# STM32F215 register map
File version: 1.2
CPU: CM3 r1p1, little endian, no MPU, no FPU, 4 interrupt priority bits
Registers are 32-bit, read-write, reset 0x0 unless marked. A register's access mark holds for its fields unless they carry their own. Offsets are from the block's base; [hi:lo] are bit positions; {n}, {i} and the like mark numbered series; 'fields as' and 'values as' point back to an identical list.

## RNG — Random number generator
Base 0x50060800
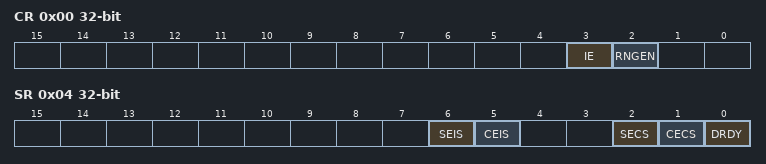
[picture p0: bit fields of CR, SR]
0x00 CR — control register
  [3] IE — Interrupt enable
  [2] RNGEN — Random number generator enable
0x04 SR access per field — status register
  [6] SEIS rw — Seed error interrupt status
  [5] CEIS rw — Clock error interrupt status
  [2] SECS ro — Seed error current status
  [1] CECS ro — Clock error current status
  [0] DRDY ro — Data ready
0x08 DR ro — data register
  [31:0] RNDATA — Random data

## CRC — cyclic redundancy check calculation unit
Base 0x40023000
0x00 DR reset 0xFFFFFFFF — Data register
  [31:0] DR — Data register bits
0x04 IDR — Independent data register
  [7:0] IDR — General-purpose 8-bit data register bits
0x08 CR wo — Control register
  [0] RESET — reset bit

## DCMI — Digital camera interface
Base 0x50050000
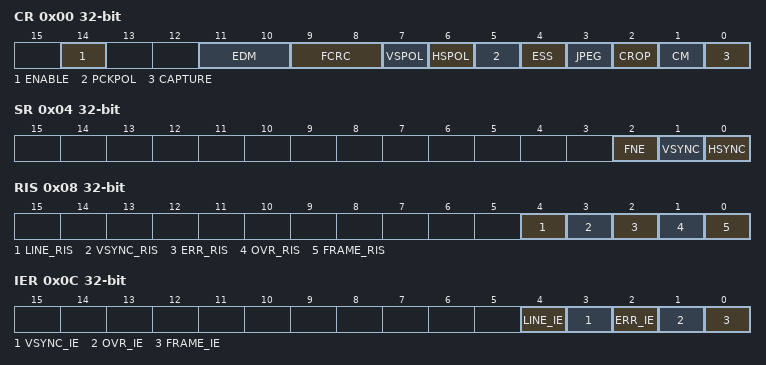
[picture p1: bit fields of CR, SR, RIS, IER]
0x00 CR — control register 1
  [14] ENABLE — DCMI enable
  [11:10] EDM — Extended data mode
  [9:8] FCRC — Frame capture rate control
  [7] VSPOL — Vertical synchronization polarity
  [6] HSPOL — Horizontal synchronization polarity
  [5] PCKPOL — Pixel clock polarity
  [4] ESS — Embedded synchronization select
  [3] JPEG — JPEG format
  [2] CROP — Crop feature
  [1] CM — Capture mode
  [0] CAPTURE — Capture enable
0x04 SR ro — status register
  [2] FNE — FIFO not empty
  [1] VSYNC
  [0] HSYNC
0x08 RIS ro — raw interrupt status register
  [4] LINE_RIS — Line raw interrupt status
  [3] VSYNC_RIS — VSYNC raw interrupt status
  [2] ERR_RIS — Synchronization error raw interrupt status
  [1] OVR_RIS — Overrun raw interrupt status
  [0] FRAME_RIS — Capture complete raw interrupt status
0x0C IER — interrupt enable register
  [4] LINE_IE — Line interrupt enable
  [3] VSYNC_IE — VSYNC interrupt enable
  [2] ERR_IE — Synchronization error interrupt enable
  [1] OVR_IE — Overrun interrupt enable
  [0] FRAME_IE — Capture complete interrupt enable
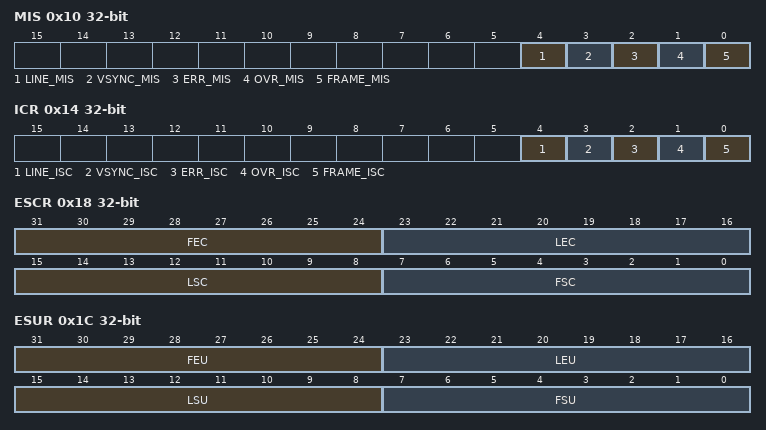
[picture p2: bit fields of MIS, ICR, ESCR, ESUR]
0x10 MIS ro — masked interrupt status register
  [4] LINE_MIS — Line masked interrupt status
  [3] VSYNC_MIS — VSYNC masked interrupt status
  [2] ERR_MIS — Synchronization error masked interrupt status
  [1] OVR_MIS — Overrun masked interrupt status
  [0] FRAME_MIS — Capture complete masked interrupt status
0x14 ICR wo — interrupt clear register
  [4] LINE_ISC — line interrupt status clear
  [3] VSYNC_ISC — Vertical synch interrupt status clear
  [2] ERR_ISC — Synchronization error interrupt status clear
  [1] OVR_ISC — Overrun interrupt status clear
  [0] FRAME_ISC — Capture complete interrupt status clear
0x18 ESCR — embedded synchronization code register
  [31:24] FEC — Frame end delimiter code
  [23:16] LEC — Line end delimiter code
  [15:8] LSC — Line start delimiter code
  [7:0] FSC — Frame start delimiter code
0x1C ESUR — embedded synchronization unmask register
  [31:24] FEU — Frame end delimiter unmask
  [23:16] LEU — Line end delimiter unmask
  [15:8] LSU — Line start delimiter unmask
  [7:0] FSU — Frame start delimiter unmask
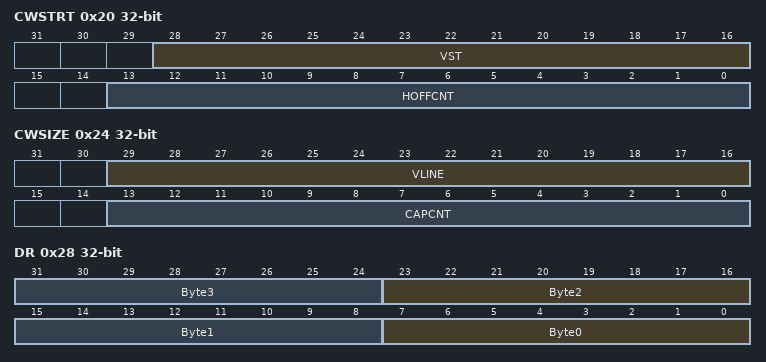
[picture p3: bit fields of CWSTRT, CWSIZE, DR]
0x20 CWSTRT — crop window start
  [28:16] VST — Vertical start line count
  [13:0] HOFFCNT — Horizontal offset count
0x24 CWSIZE — crop window size
  [29:16] VLINE — Vertical line count
  [13:0] CAPCNT — Capture count
0x28 DR ro — data register
  [8n+7:8n] Byte{n} (n=0..3) — Data byte {n}

## FSMC — Flexible static memory controller
Base 0xA0000000
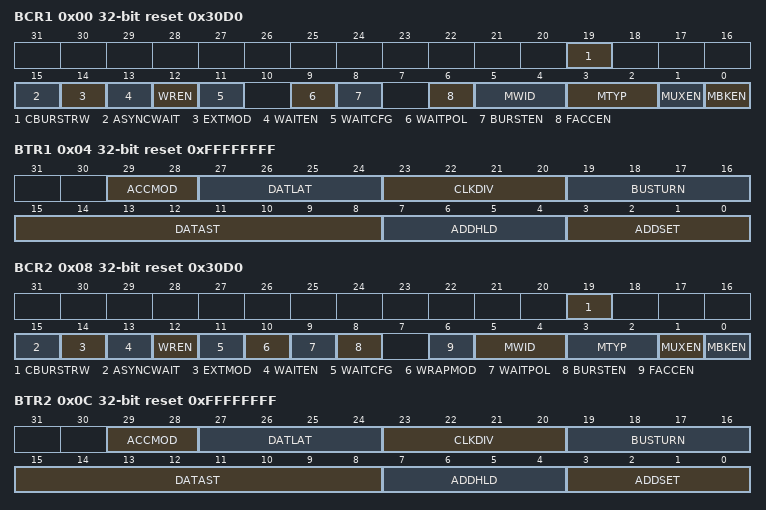
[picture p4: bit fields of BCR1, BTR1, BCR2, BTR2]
0x00 BCR1 reset 0x30D0 — SRAM/NOR-Flash chip-select control register 1
  [19] CBURSTRW, [15] ASYNCWAIT, [14] EXTMOD, [13] WAITEN, [12] WREN, [11] WAITCFG, [9] WAITPOL, [8] BURSTEN, [6] FACCEN, [5:4] MWID, [3:2] MTYP, [1] MUXEN, [0] MBKEN
0x04 BTR1 reset 0xFFFFFFFF — SRAM/NOR-Flash chip-select timing register 1
  [29:28] ACCMOD, [27:24] DATLAT, [23:20] CLKDIV, [19:16] BUSTURN, [15:8] DATAST, [7:4] ADDHLD, [3:0] ADDSET
0x08 BCR2 reset 0x30D0 — SRAM/NOR-Flash chip-select control register 2
  [19] CBURSTRW, [15] ASYNCWAIT, [14] EXTMOD, [13] WAITEN, [12] WREN, [11] WAITCFG, [10] WRAPMOD, [9] WAITPOL, [8] BURSTEN, [6] FACCEN, [5:4] MWID, [3:2] MTYP, [1] MUXEN, [0] MBKEN
0x0C BTR2 reset 0xFFFFFFFF — SRAM/NOR-Flash chip-select timing register 2
  fields as BTR1
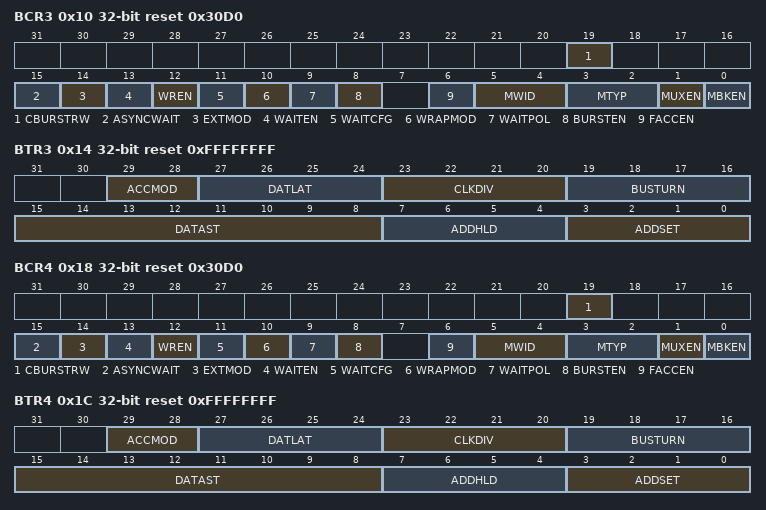
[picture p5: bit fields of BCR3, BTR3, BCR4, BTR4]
0x10 BCR3 reset 0x30D0 — SRAM/NOR-Flash chip-select control register 3
  fields as BCR2
0x14 BTR3 reset 0xFFFFFFFF — SRAM/NOR-Flash chip-select timing register 3
  fields as BTR1
0x18 BCR4 reset 0x30D0 — SRAM/NOR-Flash chip-select control register 4
  fields as BCR2
0x1C BTR4 reset 0xFFFFFFFF — SRAM/NOR-Flash chip-select timing register 4
  fields as BTR1
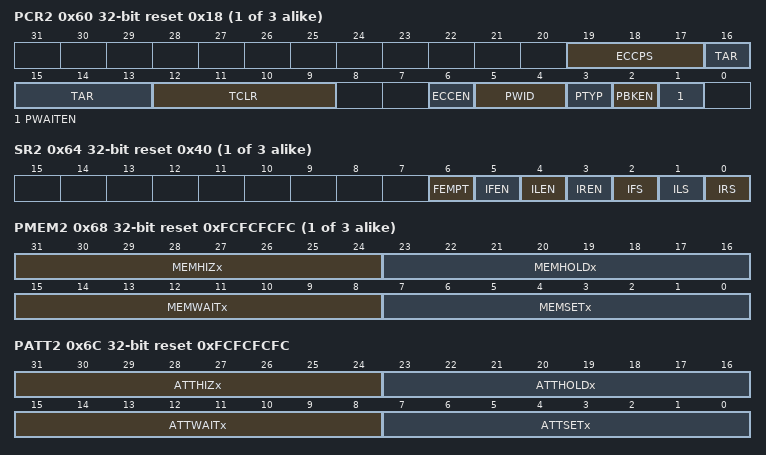
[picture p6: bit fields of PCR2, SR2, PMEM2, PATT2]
{0x20+0x20*i} PCR{i} reset 0x18 (i=2..4) — PC Card/NAND Flash control register {i}
  [19:17] ECCPS, [16:13] TAR, [12:9] TCLR, [6] ECCEN, [5:4] PWID, [3] PTYP, [2] PBKEN, [1] PWAITEN
{0x24+0x20*i} SR{i} access per field reset 0x40 (i=2..4) — FIFO status and interrupt register {i}
  [6] FEMPT ro, [5] IFEN rw, [4] ILEN rw, [3] IREN rw, [2] IFS rw, [1] ILS rw, [0] IRS rw
{0x28+0x20*i} PMEM{i} reset 0xFCFCFCFC (i=2..4) — Common memory space timing register {i}
  [31:24] MEMHIZx, [23:16] MEMHOLDx, [15:8] MEMWAITx, [7:0] MEMSETx
0x6C PATT2 reset 0xFCFCFCFC — Attribute memory space timing register 2
  [31:24] ATTHIZx — Attribute memory x databus HiZ time
  [23:16] ATTHOLDx — Attribute memory x hold time
  [15:8] ATTWAITx — Attribute memory x wait time
  [7:0] ATTSETx — Attribute memory x setup time
0x74 ECCR2 ro — ECC result register 2
  [31:0] ECCx — ECC result
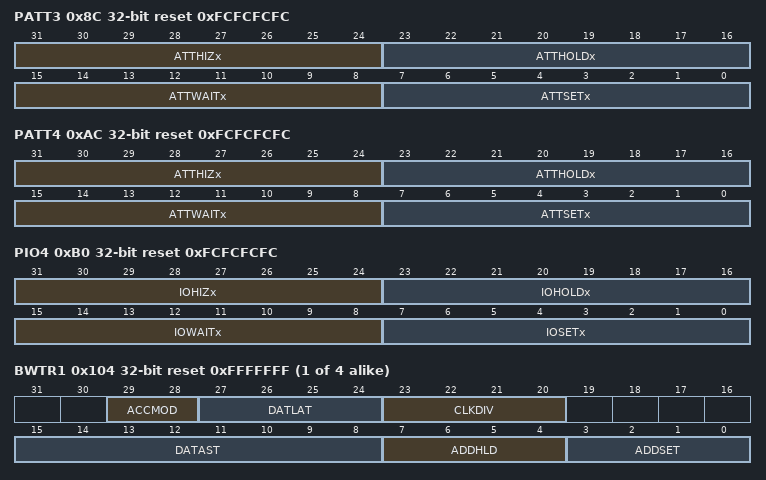
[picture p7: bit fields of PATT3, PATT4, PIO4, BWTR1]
0x8C PATT3 reset 0xFCFCFCFC — Attribute memory space timing register 3
  [31:24] ATTHIZx, [23:16] ATTHOLDx, [15:8] ATTWAITx, [7:0] ATTSETx
0x94 ECCR3 ro — ECC result register 3
  [31:0] ECCx
0xAC PATT4 reset 0xFCFCFCFC — Attribute memory space timing register 4
  [31:24] ATTHIZx, [23:16] ATTHOLDx, [15:8] ATTWAITx, [7:0] ATTSETx
0xB0 PIO4 reset 0xFCFCFCFC — I/O space timing register 4
  [31:24] IOHIZx, [23:16] IOHOLDx, [15:8] IOWAITx, [7:0] IOSETx
{0xFC+8i} BWTR{i} reset 0xFFFFFFF (i=1..4) — SRAM/NOR-Flash write timing registers {i}
  [29:28] ACCMOD, [27:24] DATLAT, [23:20] CLKDIV, [15:8] DATAST, [7:4] ADDHLD, [3:0] ADDSET
